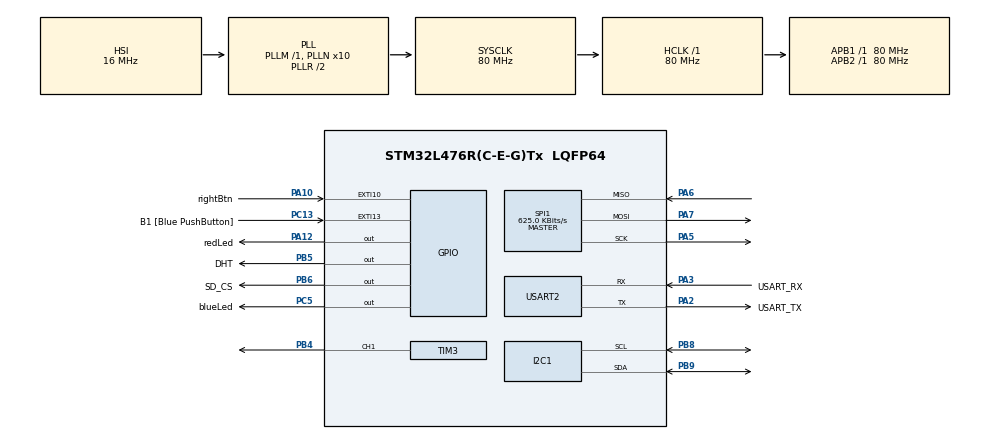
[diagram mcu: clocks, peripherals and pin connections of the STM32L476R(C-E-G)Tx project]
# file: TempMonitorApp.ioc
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FREERTOS.BinarySemaphores01=measureSemaphore,Dynamic,NULL;logSemaphore,Dynamic,NULL
FREERTOS.Mutexes01=filMutex,Dynamic,NULL
FREERTOS.Tasks01=defaultTask,16,128,StartDefaultTask,Default,NULL,Dynamic,NULL,NULL;myTask02,24,256,commTask,As external,NULL,Dynamic,NULL,NULL;myTask03,40,256,measureTemp,As external,NULL,Dynamic,NULL,NULL;myTask04,24,256,monitorTask,As external,NULL,Dynamic,NULL,NULL;myTask05,32,256,writeLog,As external,NULL,Dynamic,NULL,NULL;myTask06,24,256,accurateMeasureTime,As external,NULL,Dynamic,NULL,NULL
FREERTOS.configTOTAL_HEAP_SIZE=7000
I2C1.Timing=0x10909CEC
Mcu.Family=STM32L4
Mcu.Name=STM32L476R(C-E-G)Tx
Mcu.Package=LQFP64
NVIC.EXTI15_10_IRQn=true\:5\:0\:false\:false\:true\:true\:true\:true\:true
NVIC.PriorityGroup=NVIC_PRIORITYGROUP_4
NVIC.SPI1_IRQn=true\:5\:0\:false\:false\:true\:true\:true\:true\:true
PA10.GPIO_Label=rightBtn
PA10.Signal=GPXTI10
PA12.GPIO_Label=redLed
PA12.Signal=GPIO_Output
PA13\ (JTMS-SWDIO).GPIO_Label=TMS
PA13\ (JTMS-SWDIO).Mode=Serial_Wire
PA13\ (JTMS-SWDIO).Signal=SYS_JTMS-SWDIO
PA14\ (JTCK-SWCLK).GPIO_Label=TCK
PA14\ (JTCK-SWCLK).Mode=Serial_Wire
PA14\ (JTCK-SWCLK).Signal=SYS_JTCK-SWCLK
PA2.GPIO_Label=USART_TX
PA2.GPIO_Mode=GPIO_MODE_AF_PP
PA2.GPIO_PuPd=GPIO_NOPULL
PA2.GPIO_Speed=GPIO_SPEED_FREQ_VERY_HIGH
PA2.Mode=Asynchronous
PA2.Signal=USART2_TX
PA3.GPIO_Label=USART_RX
PA3.GPIO_Mode=GPIO_MODE_AF_PP
PA3.GPIO_PuPd=GPIO_NOPULL
PA3.GPIO_Speed=GPIO_SPEED_FREQ_VERY_HIGH
PA3.Mode=Asynchronous
PA3.Signal=USART2_RX
PA5.Mode=Full_Duplex_Master
PA5.Signal=SPI1_SCK
PA6.Mode=Full_Duplex_Master
PA6.Signal=SPI1_MISO
PA7.Mode=Full_Duplex_Master
PA7.Signal=SPI1_MOSI
PB3\ (JTDO-TRACESWO).GPIO_Label=SWO
PB3\ (JTDO-TRACESWO).Signal=SYS_JTDO-SWO
PB4\ (NJTRST).Signal=S_TIM3_CH1
PB5.GPIO_Label=DHT
PB5.Signal=GPIO_Output
PB6.GPIO_Label=SD_CS
PB6.Signal=GPIO_Output
PB8.Mode=I2C
PB8.Signal=I2C1_SCL
PB9.Mode=I2C
PB9.Signal=I2C1_SDA
PC13.GPIO_Label=B1 [Blue PushButton]
PC13.GPIO_ModeDefaultEXTI=GPIO_MODE_IT_FALLING
PC13.GPIO_PuPd=GPIO_NOPULL
PC13.Signal=GPXTI13
PC14-OSC32_IN\ (PC14).Mode=LSE-External-Oscillator
PC14-OSC32_IN\ (PC14).Signal=RCC_OSC32_IN
PC15-OSC32_OUT\ (PC15).Mode=LSE-External-Oscillator
PC15-OSC32_OUT\ (PC15).Signal=RCC_OSC32_OUT
PC5.GPIO_Label=blueLed
PC5.Signal=GPIO_Output
PH0-OSC_IN\ (PH0).Signal=RCC_OSC_IN
PH1-OSC_OUT\ (PH1).Signal=RCC_OSC_OUT
ProjectManager.HeapSize=0x400
ProjectManager.StackSize=0x800
ProjectManager.TargetToolchain=STM32CubeIDE
RCC.ADCFreq_Value=64000000
RCC.AHBFreq_Value=80000000
RCC.APB1Freq_Value=80000000
RCC.APB1TimFreq_Value=80000000
RCC.APB2Freq_Value=80000000
RCC.APB2TimFreq_Value=80000000
RCC.CortexFreq_Value=80000000
RCC.HCLKFreq_Value=80000000
RCC.HSE_VALUE=8000000
RCC.HSI_VALUE=16000000
RCC.MSI_VALUE=4000000
RCC.PLLN=10
RCC.PLLSAI1Q=RCC_PLLQ_DIV4
RCC.PLLSourceVirtual=RCC_PLLSOURCE_HSI
RCC.PREFETCH_ENABLE=1
RCC.SYSCLKFreq_VALUE=80000000
RCC.SYSCLKSource=RCC_SYSCLKSOURCE_PLLCLK
RCC.USBFreq_Value=32000000
RCC.VCOOutputFreq_Value=160000000
SH.S_TIM3_CH1.0=TIM3_CH1,PWM Generation1 CH1
SPI1.BaudRatePrescaler=SPI_BAUDRATEPRESCALER_128
SPI1.CalculateBaudRate=625.0 KBits/s
SPI1.DataSize=SPI_DATASIZE_8BIT
SPI1.Direction=SPI_DIRECTION_2LINES
SPI1.Mode=SPI_MODE_MASTER
SPI1.VirtualType=VM_MASTER
TIM3.Channel-PWM\ Generation1\ CH1=TIM_CHANNEL_1
TIM3.Period=100
TIM3.Prescaler=799
TIM3.Pulse-PWM\ Generation1\ CH1=50
TIM6.Prescaler=79
USART2.VirtualMode-Asynchronous=VM_ASYNC
VP_FATFS_VS_Generic.Mode=User_defined
VP_FREERTOS_VS_CMSIS_V2.Mode=CMSIS_V2
VP_TIM6_VS_ClockSourceINT.Mode=Enable_Timer
board=NUCLEO-L476RG

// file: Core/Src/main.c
/* USER CODE BEGIN Header */
/**
  ******************************************************************************
  * @file           : main.c
  * @brief          : Main program body
  ******************************************************************************
  * @attention
  *
  * Copyright (c) 2022 STMicroelectronics.
  * All rights reserved.
  *
  * This software is licensed under terms that can be found in the LICENSE file
  * in the root directory of this software component.
  * If no LICENSE file comes with this software, it is provided AS-IS.
  *
  ******************************************************************************
  */
/* USER CODE END Header */
#include "main.h"
#include "cmsis_os.h"
#include "fatfs.h"

/* USER CODE BEGIN Includes */
#include "commTask.h"
#include "MonitorManager.h"
/* USER CODE END Includes */

 I2C_HandleTypeDef hi2c1;

SPI_HandleTypeDef hspi1;

TIM_HandleTypeDef htim3;
TIM_HandleTypeDef htim6;

UART_HandleTypeDef huart2;

/* Definitions for defaultTask */
osThreadId_t defaultTaskHandle;
const osThreadAttr_t defaultTask_attributes = {
  .name = "defaultTask",
  .stack_size = 128 * 4,
  .priority = (osPriority_t) osPriorityBelowNormal,
};
/* Definitions for myTask02 */
osThreadId_t myTask02Handle;
const osThreadAttr_t myTask02_attributes = {
  .name = "myTask02",
  .stack_size = 256 * 4,
  .priority = (osPriority_t) osPriorityNormal,
};
/* Definitions for myTask03 */
osThreadId_t myTask03Handle;
const osThreadAttr_t myTask03_attributes = {
  .name = "myTask03",
  .stack_size = 256 * 4,
  .priority = (osPriority_t) osPriorityHigh,
};
/* Definitions for myTask04 */
osThreadId_t myTask04Handle;
const osThreadAttr_t myTask04_attributes = {
  .name = "myTask04",
  .stack_size = 256 * 4,
  .priority = (osPriority_t) osPriorityNormal,
};
/* Definitions for myTask05 */
osThreadId_t myTask05Handle;
const osThreadAttr_t myTask05_attributes = {
  .name = "myTask05",
  .stack_size = 256 * 4,
  .priority = (osPriority_t) osPriorityAboveNormal,
};
/* Definitions for myTask06 */
osThreadId_t myTask06Handle;
const osThreadAttr_t myTask06_attributes = {
  .name = "myTask06",
  .stack_size = 256 * 4,
  .priority = (osPriority_t) osPriorityNormal,
};
/* Definitions for filMutex */
osMutexId_t filMutexHandle;
const osMutexAttr_t filMutex_attributes = {
  .name = "filMutex"
};
/* Definitions for measureSemaphore */
osSemaphoreId_t measureSemaphoreHandle;
const osSemaphoreAttr_t measureSemaphore_attributes = {
  .name = "measureSemaphore"
};
/* Definitions for logSemaphore */
osSemaphoreId_t logSemaphoreHandle;
const osSemaphoreAttr_t logSemaphore_attributes = {
  .name = "logSemaphore"
};

void SystemClock_Config(void);
static void MX_GPIO_Init(void);
static void MX_USART2_UART_Init(void);
static void MX_TIM6_Init(void);
static void MX_I2C1_Init(void);
static void MX_TIM3_Init(void);
static void MX_SPI1_Init(void);
void StartDefaultTask(void *argument);
extern void commTask(void *argument);
extern void measureTemp(void *argument);
extern void monitorTask(void *argument);
extern void writeLog(void *argument);
extern void accurateMeasureTime(void *argument);

/* USER CODE BEGIN 0 */

int _write(int fd, char* ptr, int len) {
    HAL_UART_Transmit(&huart2, (uint8_t *) ptr, len, HAL_MAX_DELAY);
    return len;
}

/* USER CODE END 0 */

int main(void)
{

  /* MCU Configuration--------------------------------------------------------*/

  /* Reset of all peripherals, Initializes the Flash interface and the Systick. */
  HAL_Init();

  /* Configure the system clock */
  SystemClock_Config();

  /* Initialize all configured peripherals */
  MX_GPIO_Init();
  MX_USART2_UART_Init();
  MX_TIM6_Init();
  MX_I2C1_Init();
  MX_TIM3_Init();
  MX_SPI1_Init();
  MX_FATFS_Init();
  /* USER CODE BEGIN 2 */
  monitorInit();

  /* USER CODE END 2 */

  /* Init scheduler */
  osKernelInitialize();
  /* Create the mutex(es) */
  /* creation of filMutex */
  filMutexHandle = osMutexNew(&filMutex_attributes);

  /* Create the semaphores(s) */
  /* creation of measureSemaphore */
  measureSemaphoreHandle = osSemaphoreNew(1, 1, &measureSemaphore_attributes);

  /* creation of logSemaphore */
  logSemaphoreHandle = osSemaphoreNew(1, 1, &logSemaphore_attributes);

  /* Create the thread(s) */
  /* creation of defaultTask */
  defaultTaskHandle = osThreadNew(StartDefaultTask, NULL, &defaultTask_attributes);

  /* creation of myTask02 */
  myTask02Handle = osThreadNew(commTask, NULL, &myTask02_attributes);

  /* creation of myTask03 */
  myTask03Handle = osThreadNew(measureTemp, NULL, &myTask03_attributes);

  /* creation of myTask04 */
  myTask04Handle = osThreadNew(monitorTask, NULL, &myTask04_attributes);

  /* creation of myTask05 */
  myTask05Handle = osThreadNew(writeLog, NULL, &myTask05_attributes);

  /* creation of myTask06 */
  myTask06Handle = osThreadNew(accurateMeasureTime, NULL, &myTask06_attributes);

  /* Start scheduler */
  osKernelStart();

  /* We should never get here as control is now taken by the scheduler */
  /* Infinite loop */
  while (1)
  {

  }
}

void SystemClock_Config(void)
{
  RCC_OscInitTypeDef RCC_OscInitStruct = {0};
  RCC_ClkInitTypeDef RCC_ClkInitStruct = {0};

  /** Configure the main internal regulator output voltage
  */
  if (HAL_PWREx_ControlVoltageScaling(PWR_REGULATOR_VOLTAGE_SCALE1) != HAL_OK)
  {
    Error_Handler();
  }

  /** Initializes the RCC Oscillators according to the specified parameters
  * in the RCC_OscInitTypeDef structure.
  */
  RCC_OscInitStruct.OscillatorType = RCC_OSCILLATORTYPE_HSI;
  RCC_OscInitStruct.HSIState = RCC_HSI_ON;
  RCC_OscInitStruct.HSICalibrationValue = RCC_HSICALIBRATION_DEFAULT;
  RCC_OscInitStruct.PLL.PLLState = RCC_PLL_ON;
  RCC_OscInitStruct.PLL.PLLSource = RCC_PLLSOURCE_HSI;
  RCC_OscInitStruct.PLL.PLLM = 1;
  RCC_OscInitStruct.PLL.PLLN = 10;
  RCC_OscInitStruct.PLL.PLLP = RCC_PLLP_DIV7;
  RCC_OscInitStruct.PLL.PLLQ = RCC_PLLQ_DIV2;
  RCC_OscInitStruct.PLL.PLLR = RCC_PLLR_DIV2;
  if (HAL_RCC_OscConfig(&RCC_OscInitStruct) != HAL_OK)
  {
    Error_Handler();
  }

  /** Initializes the CPU, AHB and APB buses clocks
  */
  RCC_ClkInitStruct.ClockType = RCC_CLOCKTYPE_HCLK|RCC_CLOCKTYPE_SYSCLK
                              |RCC_CLOCKTYPE_PCLK1|RCC_CLOCKTYPE_PCLK2;
  RCC_ClkInitStruct.SYSCLKSource = RCC_SYSCLKSOURCE_PLLCLK;
  RCC_ClkInitStruct.AHBCLKDivider = RCC_SYSCLK_DIV1;
  RCC_ClkInitStruct.APB1CLKDivider = RCC_HCLK_DIV1;
  RCC_ClkInitStruct.APB2CLKDivider = RCC_HCLK_DIV1;

  if (HAL_RCC_ClockConfig(&RCC_ClkInitStruct, FLASH_LATENCY_4) != HAL_OK)
  {
    Error_Handler();
  }
}

static void MX_I2C1_Init(void)
{

  hi2c1.Instance = I2C1;
  hi2c1.Init.Timing = 0x10909CEC;
  hi2c1.Init.OwnAddress1 = 0;
  hi2c1.Init.AddressingMode = I2C_ADDRESSINGMODE_7BIT;
  hi2c1.Init.DualAddressMode = I2C_DUALADDRESS_DISABLE;
  hi2c1.Init.OwnAddress2 = 0;
  hi2c1.Init.OwnAddress2Masks = I2C_OA2_NOMASK;
  hi2c1.Init.GeneralCallMode = I2C_GENERALCALL_DISABLE;
  hi2c1.Init.NoStretchMode = I2C_NOSTRETCH_DISABLE;
  if (HAL_I2C_Init(&hi2c1) != HAL_OK)
  {
    Error_Handler();
  }

  /** Configure Analogue filter
  */
  if (HAL_I2CEx_ConfigAnalogFilter(&hi2c1, I2C_ANALOGFILTER_ENABLE) != HAL_OK)
  {
    Error_Handler();
  }

  /** Configure Digital filter
  */
  if (HAL_I2CEx_ConfigDigitalFilter(&hi2c1, 0) != HAL_OK)
  {
    Error_Handler();
  }

}

static void MX_SPI1_Init(void)
{

  /* SPI1 parameter configuration*/
  hspi1.Instance = SPI1;
  hspi1.Init.Mode = SPI_MODE_MASTER;
  hspi1.Init.Direction = SPI_DIRECTION_2LINES;
  hspi1.Init.DataSize = SPI_DATASIZE_8BIT;
  hspi1.Init.CLKPolarity = SPI_POLARITY_LOW;
  hspi1.Init.CLKPhase = SPI_PHASE_1EDGE;
  hspi1.Init.NSS = SPI_NSS_SOFT;
  hspi1.Init.BaudRatePrescaler = SPI_BAUDRATEPRESCALER_128;
  hspi1.Init.FirstBit = SPI_FIRSTBIT_MSB;
  hspi1.Init.TIMode = SPI_TIMODE_DISABLE;
  hspi1.Init.CRCCalculation = SPI_CRCCALCULATION_DISABLE;
  hspi1.Init.CRCPolynomial = 7;
  hspi1.Init.CRCLength = SPI_CRC_LENGTH_DATASIZE;
  hspi1.Init.NSSPMode = SPI_NSS_PULSE_ENABLE;
  if (HAL_SPI_Init(&hspi1) != HAL_OK)
  {
    Error_Handler();
  }

}

static void MX_TIM3_Init(void)
{

  TIM_MasterConfigTypeDef sMasterConfig = {0};
  TIM_OC_InitTypeDef sConfigOC = {0};

  htim3.Instance = TIM3;
  htim3.Init.Prescaler = 799;
  htim3.Init.CounterMode = TIM_COUNTERMODE_UP;
  htim3.Init.Period = 100;
  htim3.Init.ClockDivision = TIM_CLOCKDIVISION_DIV1;
  htim3.Init.AutoReloadPreload = TIM_AUTORELOAD_PRELOAD_DISABLE;
  if (HAL_TIM_PWM_Init(&htim3) != HAL_OK)
  {
    Error_Handler();
  }
  sMasterConfig.MasterOutputTrigger = TIM_TRGO_RESET;
  sMasterConfig.MasterSlaveMode = TIM_MASTERSLAVEMODE_DISABLE;
  if (HAL_TIMEx_MasterConfigSynchronization(&htim3, &sMasterConfig) != HAL_OK)
  {
    Error_Handler();
  }
  sConfigOC.OCMode = TIM_OCMODE_PWM1;
  sConfigOC.Pulse = 50;
  sConfigOC.OCPolarity = TIM_OCPOLARITY_HIGH;
  sConfigOC.OCFastMode = TIM_OCFAST_DISABLE;
  if (HAL_TIM_PWM_ConfigChannel(&htim3, &sConfigOC, TIM_CHANNEL_1) != HAL_OK)
  {
    Error_Handler();
  }
  HAL_TIM_MspPostInit(&htim3);

}

static void MX_TIM6_Init(void)
{

  TIM_MasterConfigTypeDef sMasterConfig = {0};

  htim6.Instance = TIM6;
  htim6.Init.Prescaler = 79;
  htim6.Init.CounterMode = TIM_COUNTERMODE_UP;
  htim6.Init.Period = 65535;
  htim6.Init.AutoReloadPreload = TIM_AUTORELOAD_PRELOAD_DISABLE;
  if (HAL_TIM_Base_Init(&htim6) != HAL_OK)
  {
    Error_Handler();
  }
  sMasterConfig.MasterOutputTrigger = TIM_TRGO_RESET;
  sMasterConfig.MasterSlaveMode = TIM_MASTERSLAVEMODE_DISABLE;
  if (HAL_TIMEx_MasterConfigSynchronization(&htim6, &sMasterConfig) != HAL_OK)
  {
    Error_Handler();
  }

}

static void MX_USART2_UART_Init(void)
{

  huart2.Instance = USART2;
  huart2.Init.BaudRate = 115200;
  huart2.Init.WordLength = UART_WORDLENGTH_8B;
  huart2.Init.StopBits = UART_STOPBITS_1;
  huart2.Init.Parity = UART_PARITY_NONE;
  huart2.Init.Mode = UART_MODE_TX_RX;
  huart2.Init.HwFlowCtl = UART_HWCONTROL_NONE;
  huart2.Init.OverSampling = UART_OVERSAMPLING_16;
  huart2.Init.OneBitSampling = UART_ONE_BIT_SAMPLE_DISABLE;
  huart2.AdvancedInit.AdvFeatureInit = UART_ADVFEATURE_NO_INIT;
  if (HAL_UART_Init(&huart2) != HAL_OK)
  {
    Error_Handler();
  }

}

static void MX_GPIO_Init(void)
{
  GPIO_InitTypeDef GPIO_InitStruct = {0};

  /* GPIO Ports Clock Enable */
  __HAL_RCC_GPIOC_CLK_ENABLE();
  __HAL_RCC_GPIOH_CLK_ENABLE();
  __HAL_RCC_GPIOA_CLK_ENABLE();
  __HAL_RCC_GPIOB_CLK_ENABLE();

  /*Configure GPIO pin Output Level */
  HAL_GPIO_WritePin(blueLed_GPIO_Port, blueLed_Pin, GPIO_PIN_RESET);

  /*Configure GPIO pin Output Level */
  HAL_GPIO_WritePin(redLed_GPIO_Port, redLed_Pin, GPIO_PIN_RESET);

  /*Configure GPIO pin Output Level */
  HAL_GPIO_WritePin(GPIOB, DHT_Pin|SD_CS_Pin, GPIO_PIN_RESET);

  /*Configure GPIO pin : B1_Pin */
  GPIO_InitStruct.Pin = B1_Pin;
  GPIO_InitStruct.Mode = GPIO_MODE_IT_FALLING;
  GPIO_InitStruct.Pull = GPIO_NOPULL;
  HAL_GPIO_Init(B1_GPIO_Port, &GPIO_InitStruct);

  /*Configure GPIO pin : blueLed_Pin */
  GPIO_InitStruct.Pin = blueLed_Pin;
  GPIO_InitStruct.Mode = GPIO_MODE_OUTPUT_PP;
  GPIO_InitStruct.Pull = GPIO_NOPULL;
  GPIO_InitStruct.Speed = GPIO_SPEED_FREQ_LOW;
  HAL_GPIO_Init(blueLed_GPIO_Port, &GPIO_InitStruct);

  /*Configure GPIO pin : rightBtn_Pin */
  GPIO_InitStruct.Pin = rightBtn_Pin;
  GPIO_InitStruct.Mode = GPIO_MODE_IT_RISING;
  GPIO_InitStruct.Pull = GPIO_NOPULL;
  HAL_GPIO_Init(rightBtn_GPIO_Port, &GPIO_InitStruct);

  /*Configure GPIO pin : redLed_Pin */
  GPIO_InitStruct.Pin = redLed_Pin;
  GPIO_InitStruct.Mode = GPIO_MODE_OUTPUT_PP;
  GPIO_InitStruct.Pull = GPIO_NOPULL;
  GPIO_InitStruct.Speed = GPIO_SPEED_FREQ_LOW;
  HAL_GPIO_Init(redLed_GPIO_Port, &GPIO_InitStruct);

  /*Configure GPIO pins : DHT_Pin SD_CS_Pin */
  GPIO_InitStruct.Pin = DHT_Pin|SD_CS_Pin;
  GPIO_InitStruct.Mode = GPIO_MODE_OUTPUT_PP;
  GPIO_InitStruct.Pull = GPIO_NOPULL;
  GPIO_InitStruct.Speed = GPIO_SPEED_FREQ_LOW;
  HAL_GPIO_Init(GPIOB, &GPIO_InitStruct);

  /* EXTI interrupt init*/
  HAL_NVIC_SetPriority(EXTI15_10_IRQn, 5, 0);
  HAL_NVIC_EnableIRQ(EXTI15_10_IRQn);

}

void StartDefaultTask(void *argument)
{
  for(;;)
  {
    osDelay(1);
  }
}

void Error_Handler(void)
{
  __disable_irq();
  while (1)
  {
  }
}
